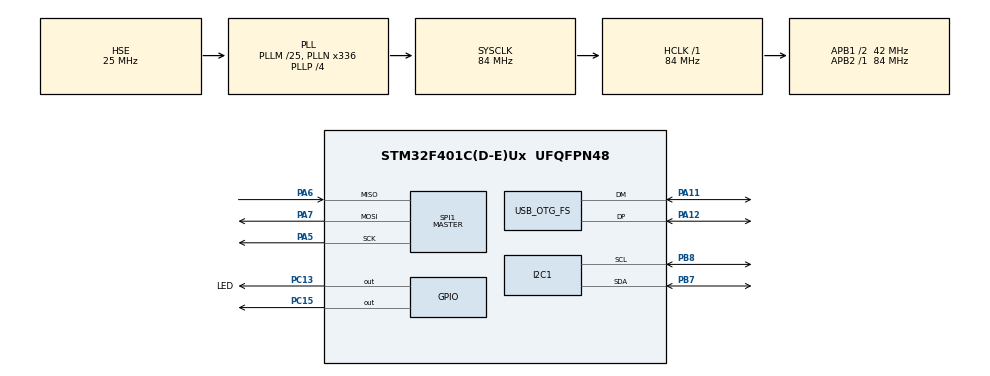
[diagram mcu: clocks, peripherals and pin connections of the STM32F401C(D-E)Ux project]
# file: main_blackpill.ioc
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Mcu.Family=STM32F4
Mcu.Name=STM32F401C(D-E)Ux
Mcu.Package=UFQFPN48
NVIC.OTG_FS_IRQn=true\:0\:0\:false\:false\:true\:false\:true\:true
NVIC.PriorityGroup=NVIC_PRIORITYGROUP_4
PA11.Mode=Device_Only
PA11.Signal=USB_OTG_FS_DM
PA12.Mode=Device_Only
PA12.Signal=USB_OTG_FS_DP
PA13.Mode=Serial_Wire
PA13.Signal=SYS_JTMS-SWDIO
PA14.Mode=Serial_Wire
PA14.Signal=SYS_JTCK-SWCLK
PA5.Mode=Full_Duplex_Master
PA5.Signal=SPI1_SCK
PA6.Mode=Full_Duplex_Master
PA6.Signal=SPI1_MISO
PA7.Mode=Full_Duplex_Master
PA7.Signal=SPI1_MOSI
PB7.GPIO_Pu=GPIO_PULLUP
PB7.Mode=I2C
PB7.Signal=I2C1_SDA
PB8.GPIO_Pu=GPIO_PULLUP
PB8.Mode=I2C
PB8.Signal=I2C1_SCL
PC13-ANTI_TAMP.GPIO_Label=LED
PC13-ANTI_TAMP.Signal=GPIO_Output
PC15-OSC32_OUT.Signal=GPIO_Output
PH0\ -\ OSC_IN.Mode=HSE-External-Oscillator
PH0\ -\ OSC_IN.Signal=RCC_OSC_IN
PH1\ -\ OSC_OUT.Mode=HSE-External-Oscillator
PH1\ -\ OSC_OUT.Signal=RCC_OSC_OUT
ProjectManager.HeapSize=0x200
ProjectManager.StackSize=0x400
ProjectManager.TargetToolchain=STM32CubeIDE
RCC.48MHZClocksFreq_Value=48000000
RCC.AHBFreq_Value=84000000
RCC.APB1CLKDivider=RCC_HCLK_DIV2
RCC.APB1Freq_Value=42000000
RCC.APB1TimFreq_Value=84000000
RCC.APB2Freq_Value=84000000
RCC.APB2TimFreq_Value=84000000
RCC.CortexFreq_Value=84000000
RCC.HCLKFreq_Value=84000000
RCC.HSE_VALUE=25000000
RCC.HSI_VALUE=16000000
RCC.LSE_VALUE=32768
RCC.PLLM=25
RCC.PLLN=336
RCC.PLLP=RCC_PLLP_DIV4
RCC.PLLQ=7
RCC.SYSCLKFreq_VALUE=84000000
RCC.SYSCLKSource=RCC_SYSCLKSOURCE_PLLCLK
RCC.VCOOutputFreq_Value=336000000
SPI1.Direction=SPI_DIRECTION_2LINES
SPI1.Mode=SPI_MODE_MASTER
SPI1.VirtualType=VM_MASTER
TIM2.AutoReloadPreload=TIM_AUTORELOAD_PRELOAD_ENABLE
TIM2.Period=65535
USB_DEVICE.CLASS_NAME_FS=CDC
USB_DEVICE.VirtualMode-CDC_FS=Cdc
USB_DEVICE.VirtualModeFS=Cdc_FS
USB_OTG_FS.VirtualMode=Device_Only
VP_TIM2_VS_ClockSourceINT.Mode=Internal
VP_USB_DEVICE_VS_USB_DEVICE_CDC_FS.Mode=CDC_FS
board=custom

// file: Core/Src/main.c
/* USER CODE BEGIN Header */
/**
  ******************************************************************************
  * @file           : main.c
  * @brief          : Main program body
  ******************************************************************************
  * @attention
  *
  * Copyright (c) 2023 STMicroelectronics.
  * All rights reserved.
  *
  * This software is licensed under terms that can be found in the LICENSE file
  * in the root directory of this software component.
  * If no LICENSE file comes with this software, it is provided AS-IS.
  *
  ******************************************************************************
  */
/* USER CODE END Header */
#include "main.h"
#include "usb_device.h"

/* USER CODE BEGIN PD */
#define IMU_WRITE_ADDRESS 0x3A
#define IMU_READ_ADDRESS 0x3B
#define arduino_add 0x55

/* USER CODE END PD */

I2C_HandleTypeDef hi2c1;

SPI_HandleTypeDef hspi1;

TIM_HandleTypeDef htim2;

void SystemClock_Config(void);
static void MX_GPIO_Init(void);
static void MX_I2C1_Init(void);
static void MX_SPI1_Init(void);
static void MX_TIM2_Init(void);

int main(void)
{
  /* USER CODE BEGIN 1 */
  uint16_t IMU[3];
  /* USER CODE END 1 */

  /* MCU Configuration--------------------------------------------------------*/

  /* Reset of all peripherals, Initializes the Flash interface and the Systick. */
  HAL_Init();

  /* Configure the system clock */
  SystemClock_Config();

  /* Initialize all configured peripherals */
  MX_GPIO_Init();
  MX_I2C1_Init();
  MX_SPI1_Init();
  MX_TIM2_Init();
  MX_USB_DEVICE_Init();
  /* USER CODE BEGIN 2 */
  HAL_TIM_Base_Start(&htim2);
  adxl_init();
  uint16_t *imu[] = {};

  /* USER CODE END 2 */

  /* Infinite loop */
  /* USER CODE BEGIN WHILE */
  while (1)
  {
	imu[0] = adxl_readx();
	imu[1] = adxl_ready();
	imu[2] = adxl_readz();

	HAL_Delay (1000);

    /* USER CODE END WHILE */

  }
}

void SystemClock_Config(void)
{
  RCC_OscInitTypeDef RCC_OscInitStruct = {0};
  RCC_ClkInitTypeDef RCC_ClkInitStruct = {0};

  /** Configure the main internal regulator output voltage
  */
  __HAL_RCC_PWR_CLK_ENABLE();
  __HAL_PWR_VOLTAGESCALING_CONFIG(PWR_REGULATOR_VOLTAGE_SCALE2);

  /** Initializes the RCC Oscillators according to the specified parameters
  * in the RCC_OscInitTypeDef structure.
  */
  RCC_OscInitStruct.OscillatorType = RCC_OSCILLATORTYPE_HSE;
  RCC_OscInitStruct.HSEState = RCC_HSE_ON;
  RCC_OscInitStruct.PLL.PLLState = RCC_PLL_ON;
  RCC_OscInitStruct.PLL.PLLSource = RCC_PLLSOURCE_HSE;
  RCC_OscInitStruct.PLL.PLLM = 25;
  RCC_OscInitStruct.PLL.PLLN = 336;
  RCC_OscInitStruct.PLL.PLLP = RCC_PLLP_DIV4;
  RCC_OscInitStruct.PLL.PLLQ = 7;
  if (HAL_RCC_OscConfig(&RCC_OscInitStruct) != HAL_OK)
  {
    Error_Handler();
  }

  /** Initializes the CPU, AHB and APB buses clocks
  */
  RCC_ClkInitStruct.ClockType = RCC_CLOCKTYPE_HCLK|RCC_CLOCKTYPE_SYSCLK
                              |RCC_CLOCKTYPE_PCLK1|RCC_CLOCKTYPE_PCLK2;
  RCC_ClkInitStruct.SYSCLKSource = RCC_SYSCLKSOURCE_PLLCLK;
  RCC_ClkInitStruct.AHBCLKDivider = RCC_SYSCLK_DIV1;
  RCC_ClkInitStruct.APB1CLKDivider = RCC_HCLK_DIV2;
  RCC_ClkInitStruct.APB2CLKDivider = RCC_HCLK_DIV1;

  if (HAL_RCC_ClockConfig(&RCC_ClkInitStruct, FLASH_LATENCY_2) != HAL_OK)
  {
    Error_Handler();
  }
}

static void MX_I2C1_Init(void)
{

  hi2c1.Instance = I2C1;
  hi2c1.Init.ClockSpeed = 100000;
  hi2c1.Init.DutyCycle = I2C_DUTYCYCLE_2;
  hi2c1.Init.OwnAddress1 = 0;
  hi2c1.Init.AddressingMode = I2C_ADDRESSINGMODE_7BIT;
  hi2c1.Init.DualAddressMode = I2C_DUALADDRESS_DISABLE;
  hi2c1.Init.OwnAddress2 = 0;
  hi2c1.Init.GeneralCallMode = I2C_GENERALCALL_DISABLE;
  hi2c1.Init.NoStretchMode = I2C_NOSTRETCH_DISABLE;
  if (HAL_I2C_Init(&hi2c1) != HAL_OK)
  {
    Error_Handler();
  }

}

static void MX_SPI1_Init(void)
{

  /* SPI1 parameter configuration*/
  hspi1.Instance = SPI1;
  hspi1.Init.Mode = SPI_MODE_MASTER;
  hspi1.Init.Direction = SPI_DIRECTION_2LINES;
  hspi1.Init.DataSize = SPI_DATASIZE_8BIT;
  hspi1.Init.CLKPolarity = SPI_POLARITY_LOW;
  hspi1.Init.CLKPhase = SPI_PHASE_1EDGE;
  hspi1.Init.NSS = SPI_NSS_SOFT;
  hspi1.Init.BaudRatePrescaler = SPI_BAUDRATEPRESCALER_2;
  hspi1.Init.FirstBit = SPI_FIRSTBIT_MSB;
  hspi1.Init.TIMode = SPI_TIMODE_DISABLE;
  hspi1.Init.CRCCalculation = SPI_CRCCALCULATION_DISABLE;
  hspi1.Init.CRCPolynomial = 10;
  if (HAL_SPI_Init(&hspi1) != HAL_OK)
  {
    Error_Handler();
  }

}

static void MX_TIM2_Init(void)
{

  TIM_ClockConfigTypeDef sClockSourceConfig = {0};
  TIM_MasterConfigTypeDef sMasterConfig = {0};

  htim2.Instance = TIM2;
  htim2.Init.Prescaler = 0;
  htim2.Init.CounterMode = TIM_COUNTERMODE_UP;
  htim2.Init.Period = 65535;
  htim2.Init.ClockDivision = TIM_CLOCKDIVISION_DIV1;
  htim2.Init.AutoReloadPreload = TIM_AUTORELOAD_PRELOAD_ENABLE;
  if (HAL_TIM_Base_Init(&htim2) != HAL_OK)
  {
    Error_Handler();
  }
  sClockSourceConfig.ClockSource = TIM_CLOCKSOURCE_INTERNAL;
  if (HAL_TIM_ConfigClockSource(&htim2, &sClockSourceConfig) != HAL_OK)
  {
    Error_Handler();
  }
  sMasterConfig.MasterOutputTrigger = TIM_TRGO_RESET;
  sMasterConfig.MasterSlaveMode = TIM_MASTERSLAVEMODE_DISABLE;
  if (HAL_TIMEx_MasterConfigSynchronization(&htim2, &sMasterConfig) != HAL_OK)
  {
    Error_Handler();
  }

}

static void MX_GPIO_Init(void)
{
  GPIO_InitTypeDef GPIO_InitStruct = {0};

  /* GPIO Ports Clock Enable */
  __HAL_RCC_GPIOC_CLK_ENABLE();
  __HAL_RCC_GPIOH_CLK_ENABLE();
  __HAL_RCC_GPIOA_CLK_ENABLE();
  __HAL_RCC_GPIOB_CLK_ENABLE();

  /*Configure GPIO pin Output Level */
  HAL_GPIO_WritePin(GPIOC, LED_Pin|GPIO_PIN_15, GPIO_PIN_RESET);

  /*Configure GPIO pins : LED_Pin PC15 */
  GPIO_InitStruct.Pin = LED_Pin|GPIO_PIN_15;
  GPIO_InitStruct.Mode = GPIO_MODE_OUTPUT_PP;
  GPIO_InitStruct.Pull = GPIO_NOPULL;
  GPIO_InitStruct.Speed = GPIO_SPEED_FREQ_LOW;
  HAL_GPIO_Init(GPIOC, &GPIO_InitStruct);

}

void Error_Handler(void)
{
  __disable_irq();
  while (1)
  {
  }
}
